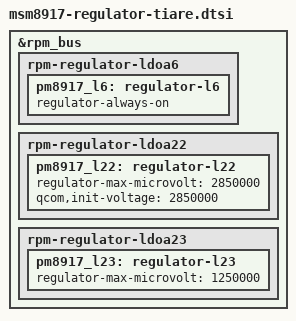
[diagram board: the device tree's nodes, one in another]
/*
 * Copyright (c) 2015-2017, The Linux Foundation. All rights reserved.
 *
 * This program is free software; you can redistribute it and/or modify
 * it under the terms of the GNU General Public License version 2 and
 * only version 2 as published by the Free Software Foundation.
 *
 * This program is distributed in the hope that it will be useful,
 * but WITHOUT ANY WARRANTY; without even the implied warranty of
 * MERCHANTABILITY or FITNESS FOR A PARTICULAR PURPOSE.  See the
 * GNU General Public License for more details.
 */

&rpm_bus {
	rpm-regulator-ldoa6 {
		pm8917_l6: regulator-l6 {
			regulator-always-on;
		};
	};

	rpm-regulator-ldoa22 {
		pm8917_l22: regulator-l22 {
			regulator-max-microvolt = <2850000>;
			qcom,init-voltage = <2850000>;
		};
	};

	rpm-regulator-ldoa23 {
		pm8917_l23: regulator-l23 {
			regulator-max-microvolt = <1250000>;
		};
	};
};	
